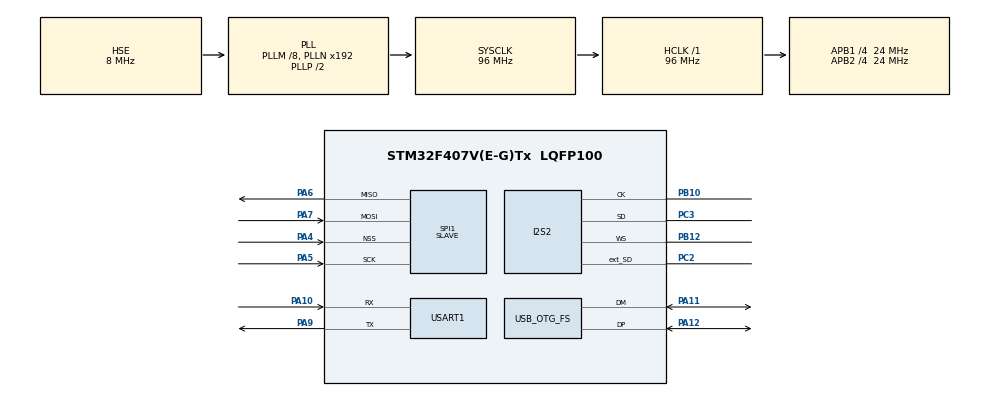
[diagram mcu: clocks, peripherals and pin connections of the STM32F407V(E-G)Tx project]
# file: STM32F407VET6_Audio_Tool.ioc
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Dma.I2S2_EXT_RX.5.Direction=DMA_PERIPH_TO_MEMORY
Dma.I2S2_EXT_RX.5.FIFOMode=DMA_FIFOMODE_DISABLE
Dma.I2S2_EXT_RX.5.Instance=DMA1_Stream3
Dma.I2S2_EXT_RX.5.MemDataAlignment=DMA_MDATAALIGN_HALFWORD
Dma.I2S2_EXT_RX.5.MemInc=DMA_MINC_ENABLE
Dma.I2S2_EXT_RX.5.Mode=DMA_CIRCULAR
Dma.I2S2_EXT_RX.5.PeriphDataAlignment=DMA_PDATAALIGN_HALFWORD
Dma.I2S2_EXT_RX.5.PeriphInc=DMA_PINC_DISABLE
Dma.I2S2_EXT_RX.5.Priority=DMA_PRIORITY_LOW
Dma.Request0=USART1_RX
Dma.Request1=USART1_TX
Dma.Request2=SPI1_RX
Dma.Request3=SPI1_TX
Dma.Request4=SPI2_TX
Dma.Request5=I2S2_EXT_RX
Dma.SPI1_RX.2.Direction=DMA_PERIPH_TO_MEMORY
Dma.SPI1_RX.2.FIFOMode=DMA_FIFOMODE_DISABLE
Dma.SPI1_RX.2.Instance=DMA2_Stream0
Dma.SPI1_RX.2.MemDataAlignment=DMA_MDATAALIGN_BYTE
Dma.SPI1_RX.2.MemInc=DMA_MINC_ENABLE
Dma.SPI1_RX.2.Mode=DMA_CIRCULAR
Dma.SPI1_RX.2.PeriphDataAlignment=DMA_PDATAALIGN_BYTE
Dma.SPI1_RX.2.PeriphInc=DMA_PINC_DISABLE
Dma.SPI1_RX.2.Priority=DMA_PRIORITY_LOW
Dma.SPI1_TX.3.Direction=DMA_MEMORY_TO_PERIPH
Dma.SPI1_TX.3.FIFOMode=DMA_FIFOMODE_DISABLE
Dma.SPI1_TX.3.Instance=DMA2_Stream3
Dma.SPI1_TX.3.MemDataAlignment=DMA_MDATAALIGN_BYTE
Dma.SPI1_TX.3.MemInc=DMA_MINC_ENABLE
Dma.SPI1_TX.3.Mode=DMA_CIRCULAR
Dma.SPI1_TX.3.PeriphDataAlignment=DMA_PDATAALIGN_BYTE
Dma.SPI1_TX.3.PeriphInc=DMA_PINC_DISABLE
Dma.SPI1_TX.3.Priority=DMA_PRIORITY_LOW
Dma.SPI2_TX.4.Direction=DMA_MEMORY_TO_PERIPH
Dma.SPI2_TX.4.FIFOMode=DMA_FIFOMODE_DISABLE
Dma.SPI2_TX.4.Instance=DMA1_Stream4
Dma.SPI2_TX.4.MemDataAlignment=DMA_MDATAALIGN_HALFWORD
Dma.SPI2_TX.4.MemInc=DMA_MINC_ENABLE
Dma.SPI2_TX.4.Mode=DMA_CIRCULAR
Dma.SPI2_TX.4.PeriphDataAlignment=DMA_PDATAALIGN_HALFWORD
Dma.SPI2_TX.4.PeriphInc=DMA_PINC_DISABLE
Dma.SPI2_TX.4.Priority=DMA_PRIORITY_LOW
Dma.USART1_RX.0.Direction=DMA_PERIPH_TO_MEMORY
Dma.USART1_RX.0.FIFOMode=DMA_FIFOMODE_DISABLE
Dma.USART1_RX.0.Instance=DMA2_Stream2
Dma.USART1_RX.0.MemDataAlignment=DMA_MDATAALIGN_BYTE
Dma.USART1_RX.0.MemInc=DMA_MINC_ENABLE
Dma.USART1_RX.0.Mode=DMA_NORMAL
Dma.USART1_RX.0.PeriphDataAlignment=DMA_PDATAALIGN_BYTE
Dma.USART1_RX.0.PeriphInc=DMA_PINC_DISABLE
Dma.USART1_RX.0.Priority=DMA_PRIORITY_LOW
Dma.USART1_TX.1.Direction=DMA_MEMORY_TO_PERIPH
Dma.USART1_TX.1.FIFOMode=DMA_FIFOMODE_DISABLE
Dma.USART1_TX.1.Instance=DMA2_Stream7
Dma.USART1_TX.1.MemDataAlignment=DMA_MDATAALIGN_BYTE
Dma.USART1_TX.1.MemInc=DMA_MINC_ENABLE
Dma.USART1_TX.1.Mode=DMA_NORMAL
Dma.USART1_TX.1.PeriphDataAlignment=DMA_PDATAALIGN_BYTE
Dma.USART1_TX.1.PeriphInc=DMA_PINC_DISABLE
Dma.USART1_TX.1.Priority=DMA_PRIORITY_LOW
I2S2.AudioFreq=I2S_AUDIOFREQ_16K
I2S2.ErrorAudioFreq=-0.26 %
I2S2.FullDuplexMode=I2S_FULLDUPLEXMODE_ENABLE
I2S2.Instance=SPI$Index
I2S2.RealAudioFreq=15.957 KHz
I2S2.VirtualMode=I2S_MODE_MASTER
Mcu.Family=STM32F4
Mcu.Name=STM32F407V(E-G)Tx
Mcu.Package=LQFP100
NVIC.DMA1_Stream3_IRQn=true\:0\:0\:false\:false\:true\:false\:true
NVIC.DMA1_Stream4_IRQn=true\:0\:0\:false\:false\:true\:false\:true
NVIC.DMA2_Stream0_IRQn=true\:0\:0\:false\:false\:true\:false\:true
NVIC.DMA2_Stream2_IRQn=true\:0\:0\:false\:false\:true\:false\:true
NVIC.DMA2_Stream3_IRQn=true\:0\:0\:false\:false\:true\:false\:true
NVIC.DMA2_Stream7_IRQn=true\:0\:0\:false\:false\:true\:false\:true
NVIC.OTG_FS_IRQn=true\:0\:0\:false\:false\:true\:false\:true
NVIC.PriorityGroup=NVIC_PRIORITYGROUP_4
NVIC.SPI1_IRQn=true\:0\:0\:false\:false\:true\:true\:true
NVIC.TIM1_UP_TIM10_IRQn=true\:0\:0\:false\:false\:true\:true\:true
NVIC.USART1_IRQn=true\:0\:0\:false\:false\:true\:true\:true
PA10.Mode=Asynchronous
PA10.Signal=USART1_RX
PA11.Mode=Device_Only
PA11.Signal=USB_OTG_FS_DM
PA12.Mode=Device_Only
PA12.Signal=USB_OTG_FS_DP
PA13.Mode=Serial_Wire
PA13.Signal=SYS_JTMS-SWDIO
PA14.Mode=Serial_Wire
PA14.Signal=SYS_JTCK-SWCLK
PA4.Mode=NSS_Signal_Hard_Input
PA4.Signal=SPI1_NSS
PA5.Mode=Full_Duplex_Slave
PA5.Signal=SPI1_SCK
PA6.Mode=Full_Duplex_Slave
PA6.Signal=SPI1_MISO
PA7.Mode=Full_Duplex_Slave
PA7.Signal=SPI1_MOSI
PA9.Mode=Asynchronous
PA9.Signal=USART1_TX
PB10.Mode=Full_Duplex_Master
PB10.Signal=I2S2_CK
PB12.Mode=Full_Duplex_Master
PB12.Signal=I2S2_WS
PC2.Mode=Full_Duplex_Master
PC2.Signal=I2S2_ext_SD
PC3.Mode=Full_Duplex_Master
PC3.Signal=I2S2_SD
PH0-OSC_IN.Mode=HSE-External-Oscillator
PH0-OSC_IN.Signal=RCC_OSC_IN
PH1-OSC_OUT.Mode=HSE-External-Oscillator
PH1-OSC_OUT.Signal=RCC_OSC_OUT
ProjectManager.HeapSize=0x1000
ProjectManager.StackSize=0x5000
ProjectManager.TargetToolchain=EWARM V8.32
RCC.48MHZClocksFreq_Value=48000000
RCC.AHBFreq_Value=96000000
RCC.APB1CLKDivider=RCC_HCLK_DIV4
RCC.APB1Freq_Value=24000000
RCC.APB1TimFreq_Value=48000000
RCC.APB2CLKDivider=RCC_HCLK_DIV4
RCC.APB2Freq_Value=24000000
RCC.APB2TimFreq_Value=48000000
RCC.CortexFreq_Value=96000000
RCC.HCLKFreq_Value=96000000
RCC.HSE_VALUE=8000000
RCC.HSI_VALUE=16000000
RCC.LSE_VALUE=32768
RCC.PLLM=8
RCC.SYSCLKFreq_VALUE=96000000
RCC.SYSCLKSource=RCC_SYSCLKSOURCE_PLLCLK
RCC.VCOOutputFreq_Value=192000000
SPI1.CRCCalculation=SPI_CRCCALCULATION_ENABLE
SPI1.Direction=SPI_DIRECTION_2LINES
SPI1.FirstBit=SPI_FIRSTBIT_MSB
SPI1.Mode=SPI_MODE_SLAVE
SPI1.VirtualNSS=VM_NSSHARD
SPI1.VirtualType=VM_SLAVE
TIM1.AutoReloadPreload=TIM_AUTORELOAD_PRELOAD_ENABLE
TIM1.Period=10000-1
TIM1.Prescaler=48-1
USART1.VirtualMode=VM_ASYNC
USB_DEVICE.CLASS_NAME_FS=CDC
USB_DEVICE.VirtualMode-CDC_FS=Cdc
USB_DEVICE.VirtualModeFS=Cdc_FS
USB_OTG_FS.VirtualMode=Device_Only
VP_TIM1_VS_ClockSourceINT.Mode=Internal
VP_USB_DEVICE_VS_USB_DEVICE_CDC_FS.Mode=CDC_FS
board=custom

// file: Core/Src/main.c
/* USER CODE BEGIN Header */
/**
  ******************************************************************************
  * @file           : main.c
  * @brief          : Main program body
  ******************************************************************************
  * @attention
  *
  * <h2><center>&copy; Copyright (c) 2021 STMicroelectronics.
  * All rights reserved.</center></h2>
  *
  * This software component is licensed by ST under Ultimate Liberty license
  * SLA0044, the "License"; You may not use this file except in compliance with
  * the License. You may obtain a copy of the License at:
  *                             www.st.com/SLA0044
  *
  ******************************************************************************
  */
/* USER CODE END Header */
#include "main.h"
#include "dma.h"
#include "i2s.h"
#include "spi.h"
#include "tim.h"
#include "usart.h"
#include "usb_device.h"
#include "gpio.h"

/* USER CODE BEGIN Includes */
#include <string.h>
#include <stdio.h>
/* USER CODE END Includes */

void SystemClock_Config(void);

int main(void)
{

  /* MCU Configuration--------------------------------------------------------*/

  /* Reset of all peripherals, Initializes the Flash interface and the Systick. */
  HAL_Init();

  /* Configure the system clock */
  SystemClock_Config();

  /* Initialize all configured peripherals */
  MX_GPIO_Init();
  MX_DMA_Init();
  MX_USART1_UART_Init();
  MX_SPI1_Init();
  MX_USB_DEVICE_Init();
  MX_I2S2_Init();
  MX_TIM1_Init();
  /* USER CODE BEGIN 2 */
  User_Main_Init();
  /* USER CODE END 2 */

  /* Infinite loop */
  while (1)
  {

    /* USER CODE BEGIN 3 */
    User_Main_Loop();
  }
  /* USER CODE END 3 */
}

void SystemClock_Config(void)
{
  RCC_OscInitTypeDef RCC_OscInitStruct = {0};
  RCC_ClkInitTypeDef RCC_ClkInitStruct = {0};

  /** Configure the main internal regulator output voltage
  */
  __HAL_RCC_PWR_CLK_ENABLE();
  __HAL_PWR_VOLTAGESCALING_CONFIG(PWR_REGULATOR_VOLTAGE_SCALE1);
  /** Initializes the RCC Oscillators according to the specified parameters
  * in the RCC_OscInitTypeDef structure.
  */
  RCC_OscInitStruct.OscillatorType = RCC_OSCILLATORTYPE_HSE;
  RCC_OscInitStruct.HSEState = RCC_HSE_ON;
  RCC_OscInitStruct.PLL.PLLState = RCC_PLL_ON;
  RCC_OscInitStruct.PLL.PLLSource = RCC_PLLSOURCE_HSE;
  RCC_OscInitStruct.PLL.PLLM = 8;
  RCC_OscInitStruct.PLL.PLLN = 192;
  RCC_OscInitStruct.PLL.PLLP = RCC_PLLP_DIV2;
  RCC_OscInitStruct.PLL.PLLQ = 4;
  if (HAL_RCC_OscConfig(&RCC_OscInitStruct) != HAL_OK)
  {
    Error_Handler();
  }
  /** Initializes the CPU, AHB and APB buses clocks
  */
  RCC_ClkInitStruct.ClockType = RCC_CLOCKTYPE_HCLK|RCC_CLOCKTYPE_SYSCLK
                              |RCC_CLOCKTYPE_PCLK1|RCC_CLOCKTYPE_PCLK2;
  RCC_ClkInitStruct.SYSCLKSource = RCC_SYSCLKSOURCE_PLLCLK;
  RCC_ClkInitStruct.AHBCLKDivider = RCC_SYSCLK_DIV1;
  RCC_ClkInitStruct.APB1CLKDivider = RCC_HCLK_DIV4;
  RCC_ClkInitStruct.APB2CLKDivider = RCC_HCLK_DIV4;

  if (HAL_RCC_ClockConfig(&RCC_ClkInitStruct, FLASH_LATENCY_3) != HAL_OK)
  {
    Error_Handler();
  }
}

void Error_Handler(void)
{
  __disable_irq();
  while (1)
  {
  }
}

/************************ (C) COPYRIGHT STMicroelectronics *****END OF FILE****/
